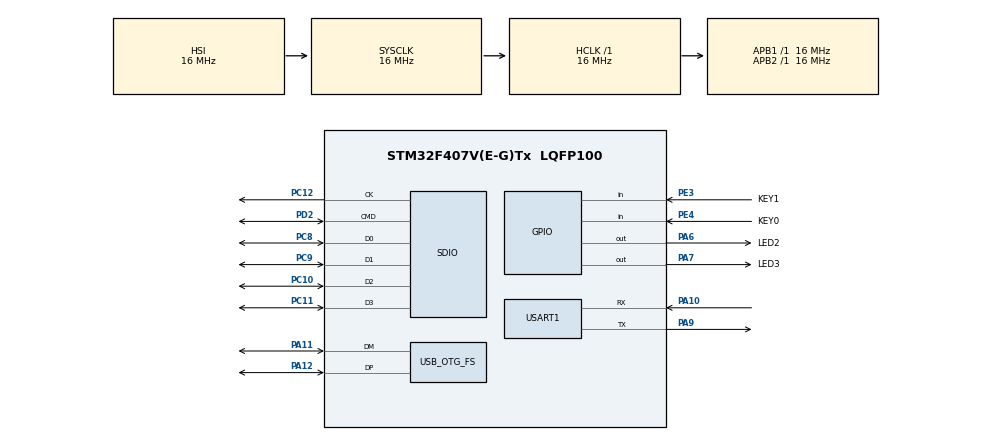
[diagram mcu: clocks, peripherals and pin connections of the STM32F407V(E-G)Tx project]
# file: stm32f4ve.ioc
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Mcu.Family=STM32F4
Mcu.Name=STM32F407V(E-G)Tx
Mcu.Package=LQFP100
NVIC.PriorityGroup=NVIC_PRIORITYGROUP_4
PA10.Mode=Multiprocessor_communication
PA10.Signal=USART1_RX
PA11.Mode=Host_Only
PA11.Signal=USB_OTG_FS_DM
PA12.Mode=Host_Only
PA12.Signal=USB_OTG_FS_DP
PA13.Mode=Serial_Wire
PA13.Signal=SYS_JTMS-SWDIO
PA14.Mode=Serial_Wire
PA14.Signal=SYS_JTCK-SWCLK
PA6.GPIO_Label=LED2
PA6.GPIO_ModeDefaultOutputPP=GPIO_MODE_OUTPUT_PP
PA6.GPIO_PuPd=GPIO_PULLUP
PA6.PinState=GPIO_PIN_SET
PA6.Signal=GPIO_Output
PA7.GPIO_Label=LED3
PA7.GPIO_PuPd=GPIO_PULLUP
PA7.PinState=GPIO_PIN_SET
PA7.Signal=GPIO_Output
PA9.Mode=Multiprocessor_communication
PA9.Signal=USART1_TX
PB3.Signal=SPI1_SCK
PB4.Signal=SPI1_MISO
PB5.Signal=SPI1_MOSI
PC10.Mode=SD_4_bits_Wide_bus
PC10.Signal=SDIO_D2
PC11.Mode=SD_4_bits_Wide_bus
PC11.Signal=SDIO_D3
PC12.Mode=SD_4_bits_Wide_bus
PC12.Signal=SDIO_CK
PC14-OSC32_IN.Mode=LSE-External-Oscillator
PC14-OSC32_IN.Signal=RCC_OSC32_IN
PC15-OSC32_OUT.Mode=LSE-External-Oscillator
PC15-OSC32_OUT.Signal=RCC_OSC32_OUT
PC8.Mode=SD_4_bits_Wide_bus
PC8.Signal=SDIO_D0
PC9.Mode=SD_4_bits_Wide_bus
PC9.Signal=SDIO_D1
PD2.Mode=SD_4_bits_Wide_bus
PD2.Signal=SDIO_CMD
PE3.GPIO_Label=KEY1
PE3.GPIO_PuPd=GPIO_PULLUP
PE3.Signal=GPIO_Input
PE4.GPIO_Label=KEY0
PE4.GPIO_PuPd=GPIO_PULLUP
PE4.Signal=GPIO_Input
PH0-OSC_IN.Mode=HSE-External-Oscillator
PH0-OSC_IN.Signal=RCC_OSC_IN
PH1-OSC_OUT.Mode=HSE-External-Oscillator
PH1-OSC_OUT.Signal=RCC_OSC_OUT
ProjectManager.HeapSize=0x200
ProjectManager.StackSize=0x400
ProjectManager.TargetToolchain=TrueSTUDIO
RCC.48MHZClocksFreq_Value=48000000
RCC.AHBFreq_Value=16000000
RCC.APB1Freq_Value=16000000
RCC.APB2Freq_Value=16000000
RCC.CortexFreq_Value=16000000
RCC.HSE_VALUE=8000000
RCC.HSI_VALUE=16000000
RCC.PLLM=8
RCC.PLLN=240
RCC.PLLQ=5
RCC.SYSCLKFreq_VALUE=16000000
RCC.VCOOutputFreq_Value=240000000
USART1.VirtualMode=VM_ASYNC
USB_OTG_FS.VirtualMode=Host_Only
USB_OTG_FS.phy_itface=HCD_PHY_EMBEDDED
VP_CRC_VS_CRC.Mode=CRC_Activate
VP_RNG_VS_RNG.Mode=RNG_Activate
VP_RTC_VS_RTC_Activate.Mode=RTC_Enabled
VP_TIM12_VS_ClockSourceITR.Mode=TriggerSource_ITR0
board=stm32f4ve

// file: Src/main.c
/* USER CODE BEGIN Header */
/**
  ******************************************************************************
  * @file           : main.c
  * @brief          : Main program body
  ******************************************************************************
  * @attention
  *
  * <h2><center>&copy; Copyright (c) 2019 STMicroelectronics.
  * All rights reserved.</center></h2>
  *
  * This software component is licensed by ST under BSD 3-Clause license,
  * the "License"; You may not use this file except in compliance with the
  * License. You may obtain a copy of the License at:
  *                        opensource.org/licenses/BSD-3-Clause
  *
  ******************************************************************************
  */
/* USER CODE END Header */

#include "main.h"

/* USER CODE BEGIN Includes */
#include "delay.h"
/* USER CODE END Includes */

CRC_HandleTypeDef hcrc;

RNG_HandleTypeDef hrng;

RTC_HandleTypeDef hrtc;

SD_HandleTypeDef hsd;

TIM_HandleTypeDef htim12;

UART_HandleTypeDef huart1;

HCD_HandleTypeDef hhcd_USB_OTG_FS;

void SystemClock_Config(void);
static void MX_GPIO_Init(void);
static void MX_USART1_UART_Init(void);
static void MX_SDIO_SD_Init(void);
static void MX_CRC_Init(void);
static void MX_TIM12_Init(void);
static void MX_RNG_Init(void);
static void MX_USB_OTG_FS_HCD_Init(void);
static void MX_RTC_Init(void);

int main(void)
{

  /* MCU Configuration--------------------------------------------------------*/

  /* Reset of all peripherals, Initializes the Flash interface and the Systick. */
  HAL_Init();

  /* Configure the system clock */
  SystemClock_Config();

  /* Initialize all configured peripherals */
  MX_GPIO_Init();
  MX_USART1_UART_Init();
  MX_SDIO_SD_Init();
  MX_CRC_Init();
  MX_TIM12_Init();
  MX_RNG_Init();
  MX_USB_OTG_FS_HCD_Init();
  MX_RTC_Init();
  /* USER CODE BEGIN 2 */

  GPIO_PinState key_0 = GPIO_PIN_RESET;
  GPIO_PinState LED_2 = GPIO_PIN_RESET;
  uint8_t timer_led2_id = 0;
  Set_timing_delay(500,timer_led2_id);
  /* USER CODE END 2 */

  /* Infinite loop */
	while (1)
	{

    /* USER CODE BEGIN 3 */
		if(Get_timing_delay(timer_led2_id) <= 0)
		{
			if(LED_2 == GPIO_PIN_RESET)
			{
				LED_2 = GPIO_PIN_SET;
			}
			else
			{
				LED_2 = GPIO_PIN_RESET;
			}
			HAL_GPIO_WritePin(LED2_GPIO_Port,LED2_Pin,LED_2);
			Set_timing_delay(500,timer_led2_id); //set a timer of 500 again
		}
		  key_0 = HAL_GPIO_ReadPin(KEY0_GPIO_Port,KEY0_Pin);
		  HAL_GPIO_WritePin(LED3_GPIO_Port, LED3_Pin, key_0);
	}
  /* USER CODE END 3 */
}

void SystemClock_Config(void)
{
  RCC_OscInitTypeDef RCC_OscInitStruct = {0};
  RCC_ClkInitTypeDef RCC_ClkInitStruct = {0};
  RCC_PeriphCLKInitTypeDef PeriphClkInitStruct = {0};

  /** Configure the main internal regulator output voltage
  */
  __HAL_RCC_PWR_CLK_ENABLE();
  __HAL_PWR_VOLTAGESCALING_CONFIG(PWR_REGULATOR_VOLTAGE_SCALE1);
  /** Initializes the CPU, AHB and APB busses clocks
  */
  RCC_OscInitStruct.OscillatorType = RCC_OSCILLATORTYPE_HSI|RCC_OSCILLATORTYPE_LSI
                              |RCC_OSCILLATORTYPE_HSE;
  RCC_OscInitStruct.HSEState = RCC_HSE_ON;
  RCC_OscInitStruct.HSIState = RCC_HSI_ON;
  RCC_OscInitStruct.HSICalibrationValue = RCC_HSICALIBRATION_DEFAULT;
  RCC_OscInitStruct.LSIState = RCC_LSI_ON;
  RCC_OscInitStruct.PLL.PLLState = RCC_PLL_ON;
  RCC_OscInitStruct.PLL.PLLSource = RCC_PLLSOURCE_HSE;
  RCC_OscInitStruct.PLL.PLLM = 8;
  RCC_OscInitStruct.PLL.PLLN = 240;
  RCC_OscInitStruct.PLL.PLLP = RCC_PLLP_DIV2;
  RCC_OscInitStruct.PLL.PLLQ = 5;
  if (HAL_RCC_OscConfig(&RCC_OscInitStruct) != HAL_OK)
  {
    Error_Handler();
  }
  /** Initializes the CPU, AHB and APB busses clocks
  */
  RCC_ClkInitStruct.ClockType = RCC_CLOCKTYPE_HCLK|RCC_CLOCKTYPE_SYSCLK
                              |RCC_CLOCKTYPE_PCLK1|RCC_CLOCKTYPE_PCLK2;
  RCC_ClkInitStruct.SYSCLKSource = RCC_SYSCLKSOURCE_HSI;
  RCC_ClkInitStruct.AHBCLKDivider = RCC_SYSCLK_DIV1;
  RCC_ClkInitStruct.APB1CLKDivider = RCC_HCLK_DIV1;
  RCC_ClkInitStruct.APB2CLKDivider = RCC_HCLK_DIV1;

  if (HAL_RCC_ClockConfig(&RCC_ClkInitStruct, FLASH_LATENCY_0) != HAL_OK)
  {
    Error_Handler();
  }
  PeriphClkInitStruct.PeriphClockSelection = RCC_PERIPHCLK_RTC;
  PeriphClkInitStruct.RTCClockSelection = RCC_RTCCLKSOURCE_LSI;
  if (HAL_RCCEx_PeriphCLKConfig(&PeriphClkInitStruct) != HAL_OK)
  {
    Error_Handler();
  }
}

static void MX_CRC_Init(void)
{

  hcrc.Instance = CRC;
  if (HAL_CRC_Init(&hcrc) != HAL_OK)
  {
    Error_Handler();
  }

}

static void MX_RNG_Init(void)
{

  hrng.Instance = RNG;
  if (HAL_RNG_Init(&hrng) != HAL_OK)
  {
    Error_Handler();
  }

}

static void MX_RTC_Init(void)
{

  /** Initialize RTC Only
  */
  hrtc.Instance = RTC;
  hrtc.Init.HourFormat = RTC_HOURFORMAT_24;
  hrtc.Init.AsynchPrediv = 127;
  hrtc.Init.SynchPrediv = 255;
  hrtc.Init.OutPut = RTC_OUTPUT_DISABLE;
  hrtc.Init.OutPutPolarity = RTC_OUTPUT_POLARITY_HIGH;
  hrtc.Init.OutPutType = RTC_OUTPUT_TYPE_OPENDRAIN;
  if (HAL_RTC_Init(&hrtc) != HAL_OK)
  {
    Error_Handler();
  }

}

static void MX_SDIO_SD_Init(void)
{

  hsd.Instance = SDIO;
  hsd.Init.ClockEdge = SDIO_CLOCK_EDGE_RISING;
  hsd.Init.ClockBypass = SDIO_CLOCK_BYPASS_DISABLE;
  hsd.Init.ClockPowerSave = SDIO_CLOCK_POWER_SAVE_DISABLE;
  hsd.Init.BusWide = SDIO_BUS_WIDE_1B;
  hsd.Init.HardwareFlowControl = SDIO_HARDWARE_FLOW_CONTROL_DISABLE;
  hsd.Init.ClockDiv = 0;
  if (HAL_SD_Init(&hsd) != HAL_OK)
  {
    Error_Handler();
  }
  if (HAL_SD_ConfigWideBusOperation(&hsd, SDIO_BUS_WIDE_4B) != HAL_OK)
  {
    Error_Handler();
  }

}

static void MX_TIM12_Init(void)
{

  TIM_SlaveConfigTypeDef sSlaveConfig = {0};

  htim12.Instance = TIM12;
  htim12.Init.Prescaler = 0;
  htim12.Init.CounterMode = TIM_COUNTERMODE_UP;
  htim12.Init.Period = 0;
  htim12.Init.ClockDivision = TIM_CLOCKDIVISION_DIV1;
  htim12.Init.AutoReloadPreload = TIM_AUTORELOAD_PRELOAD_DISABLE;
  if (HAL_TIM_Base_Init(&htim12) != HAL_OK)
  {
    Error_Handler();
  }
  sSlaveConfig.SlaveMode = TIM_SLAVEMODE_DISABLE;
  sSlaveConfig.InputTrigger = TIM_TS_ITR0;
  if (HAL_TIM_SlaveConfigSynchro(&htim12, &sSlaveConfig) != HAL_OK)
  {
    Error_Handler();
  }

}

static void MX_USART1_UART_Init(void)
{

  huart1.Instance = USART1;
  huart1.Init.BaudRate = 115200;
  huart1.Init.WordLength = UART_WORDLENGTH_8B;
  huart1.Init.StopBits = UART_STOPBITS_1;
  huart1.Init.Parity = UART_PARITY_NONE;
  huart1.Init.Mode = UART_MODE_TX_RX;
  huart1.Init.HwFlowCtl = UART_HWCONTROL_NONE;
  huart1.Init.OverSampling = UART_OVERSAMPLING_16;
  if (HAL_MultiProcessor_Init(&huart1, 0, UART_WAKEUPMETHOD_IDLELINE) != HAL_OK)
  {
    Error_Handler();
  }

}

static void MX_USB_OTG_FS_HCD_Init(void)
{

  hhcd_USB_OTG_FS.Instance = USB_OTG_FS;
  hhcd_USB_OTG_FS.Init.Host_channels = 8;
  hhcd_USB_OTG_FS.Init.speed = HCD_SPEED_FULL;
  hhcd_USB_OTG_FS.Init.dma_enable = DISABLE;
  hhcd_USB_OTG_FS.Init.phy_itface = HCD_PHY_EMBEDDED;
  hhcd_USB_OTG_FS.Init.Sof_enable = DISABLE;
  if (HAL_HCD_Init(&hhcd_USB_OTG_FS) != HAL_OK)
  {
    Error_Handler();
  }

}

static void MX_GPIO_Init(void)
{
  GPIO_InitTypeDef GPIO_InitStruct = {0};

  /* GPIO Ports Clock Enable */
  __HAL_RCC_GPIOE_CLK_ENABLE();
  __HAL_RCC_GPIOC_CLK_ENABLE();
  __HAL_RCC_GPIOH_CLK_ENABLE();
  __HAL_RCC_GPIOA_CLK_ENABLE();
  __HAL_RCC_GPIOD_CLK_ENABLE();
  __HAL_RCC_GPIOB_CLK_ENABLE();

  /*Configure GPIO pin Output Level */
  HAL_GPIO_WritePin(GPIOA, LED2_Pin|LED3_Pin, GPIO_PIN_SET);

  /*Configure GPIO pins : KEY1_Pin KEY0_Pin */
  GPIO_InitStruct.Pin = KEY1_Pin|KEY0_Pin;
  GPIO_InitStruct.Mode = GPIO_MODE_INPUT;
  GPIO_InitStruct.Pull = GPIO_PULLUP;
  HAL_GPIO_Init(GPIOE, &GPIO_InitStruct);

  /*Configure GPIO pins : LED2_Pin LED3_Pin */
  GPIO_InitStruct.Pin = LED2_Pin|LED3_Pin;
  GPIO_InitStruct.Mode = GPIO_MODE_OUTPUT_PP;
  GPIO_InitStruct.Pull = GPIO_PULLUP;
  GPIO_InitStruct.Speed = GPIO_SPEED_FREQ_LOW;
  HAL_GPIO_Init(GPIOA, &GPIO_InitStruct);

  /*Configure GPIO pins : PB3 PB4 PB5 */
  GPIO_InitStruct.Pin = GPIO_PIN_3|GPIO_PIN_4|GPIO_PIN_5;
  GPIO_InitStruct.Mode = GPIO_MODE_AF_PP;
  GPIO_InitStruct.Pull = GPIO_NOPULL;
  GPIO_InitStruct.Speed = GPIO_SPEED_FREQ_VERY_HIGH;
  GPIO_InitStruct.Alternate = GPIO_AF5_SPI1;
  HAL_GPIO_Init(GPIOB, &GPIO_InitStruct);

}

void Error_Handler(void)
{
}

/************************ (C) COPYRIGHT STMicroelectronics *****END OF FILE****/
